# PIC16F1619 register map
File version: 1.0
Registers are 8-bit, read-write, reset 0x0 unless marked. A register's access mark holds for its fields unless they carry their own. Offsets are from the block's base; [hi:lo] are bit positions; {n}, {i} and the like mark numbered series.

## COMPARATORS
Base 0x00800111
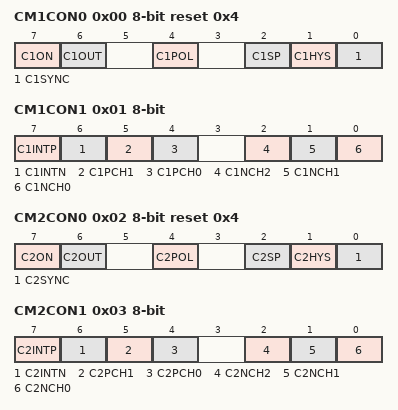
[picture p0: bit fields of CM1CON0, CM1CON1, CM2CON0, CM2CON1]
0x00 CM1CON0 reset 0x4 — CM1CON0, data address 0x111
  [7] C1ON, [6] C1OUT, [4] C1POL, [2] C1SP, [1] C1HYS, [0] C1SYNC
0x01 CM1CON1 — CM1CON1, data address 0x112
  [7] C1INTP, [6] C1INTN, [5] C1PCH1, [4] C1PCH0, [2] C1NCH2, [1] C1NCH1, [0] C1NCH0
0x02 CM2CON0 reset 0x4 — CM2CON0, data address 0x113
  [7] C2ON, [6] C2OUT, [4] C2POL, [2] C2SP, [1] C2HYS, [0] C2SYNC
0x03 CM2CON1 — CM2CON1, data address 0x114
  [7] C2INTP, [6] C2INTN, [5] C2PCH1, [4] C2PCH0, [2] C2NCH2, [1] C2NCH1, [0] C2NCH0
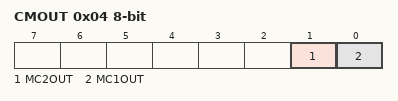
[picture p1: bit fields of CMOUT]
0x04 CMOUT — CMOUT, data address 0x115
  [1] MC2OUT, [0] MC1OUT

## EUSART
Base 0x00800199
0x00 RC1REG — RC1REG, data address 0x199
0x01 TX1REG — TX1REG, data address 0x19a
0x02 SP1BRGL — SP1BRGL, data address 0x19b
0x03 SP1BRGH — SP1BRGH, data address 0x19c
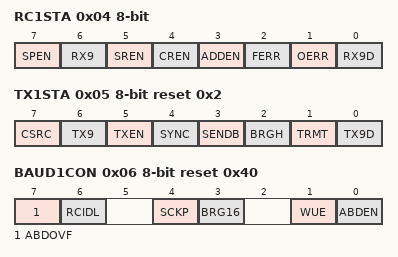
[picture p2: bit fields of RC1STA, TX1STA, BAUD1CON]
0x04 RC1STA — RC1STA, data address 0x19d
  [7] SPEN, [6] RX9, [5] SREN, [4] CREN, [3] ADDEN, [2] FERR, [1] OERR, [0] RX9D
0x05 TX1STA reset 0x2 — TX1STA, data address 0x19e
  [7] CSRC, [6] TX9, [5] TXEN, [4] SYNC, [3] SENDB, [2] BRGH, [1] TRMT, [0] TX9D
0x06 BAUD1CON reset 0x40 — BAUD1CON, data address 0x19f
  [7] ABDOVF, [6] RCIDL, [4] SCKP, [3] BRG16, [1] WUE, [0] ABDEN

## INTERRUPTS — Interrupt flags and enables
Base 0x00800010
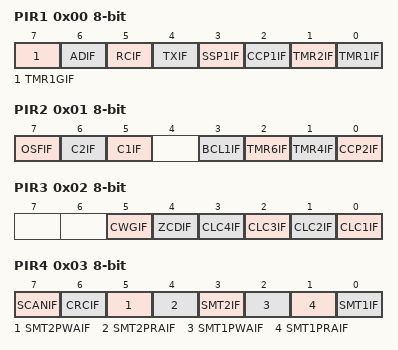
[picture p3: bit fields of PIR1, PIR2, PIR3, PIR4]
0x00 PIR1 — PIR1, data address 0x010
  [7] TMR1GIF, [6] ADIF, [5] RCIF, [4] TXIF, [3] SSP1IF, [2] CCP1IF, [1] TMR2IF, [0] TMR1IF
0x01 PIR2 — PIR2, data address 0x011
  [7] OSFIF, [6] C2IF, [5] C1IF, [3] BCL1IF, [2] TMR6IF, [1] TMR4IF, [0] CCP2IF
0x02 PIR3 — PIR3, data address 0x012
  [5] CWGIF, [4] ZCDIF, [n-1] CLC{n}IF (n=1..4)
0x03 PIR4 — PIR4, data address 0x013
  [7] SCANIF, [6] CRCIF, [5] SMT2PWAIF, [4] SMT2PRAIF, [3] SMT2IF, [2] SMT1PWAIF, [1] SMT1PRAIF, [0] SMT1IF
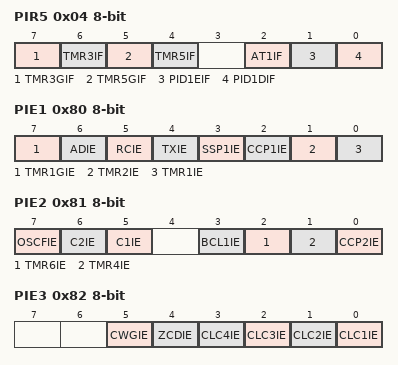
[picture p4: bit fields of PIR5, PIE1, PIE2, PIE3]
0x04 PIR5 — PIR5, data address 0x014
  [7] TMR3GIF, [6] TMR3IF, [5] TMR5GIF, [4] TMR5IF, [2] AT1IF, [1] PID1EIF, [0] PID1DIF
0x80 PIE1 — PIE1, data address 0x090
  [7] TMR1GIE, [6] ADIE, [5] RCIE, [4] TXIE, [3] SSP1IE, [2] CCP1IE, [1] TMR2IE, [0] TMR1IE
0x81 PIE2 — PIE2, data address 0x091
  [7] OSCFIE, [6] C2IE, [5] C1IE, [3] BCL1IE, [2] TMR6IE, [1] TMR4IE, [0] CCP2IE
0x82 PIE3 — PIE3, data address 0x092
  [5] CWGIE, [4] ZCDIE, [n-1] CLC{n}IE (n=1..4)
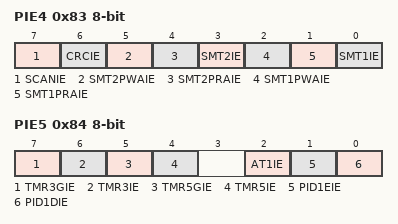
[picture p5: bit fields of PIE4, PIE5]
0x83 PIE4 — PIE4, data address 0x093
  [7] SCANIE, [6] CRCIE, [5] SMT2PWAIE, [4] SMT2PRAIE, [3] SMT2IE, [2] SMT1PWAIE, [1] SMT1PRAIE, [0] SMT1IE
0x84 PIE5 reset not defined — PIE5, data address 0x094
  [7] TMR3GIE, [6] TMR3IE, [5] TMR5GIE, [4] TMR5IE, [2] AT1IE, [1] PID1EIE, [0] PID1DIE

## MSSP — Synchronous serial port
Base 0x00800211
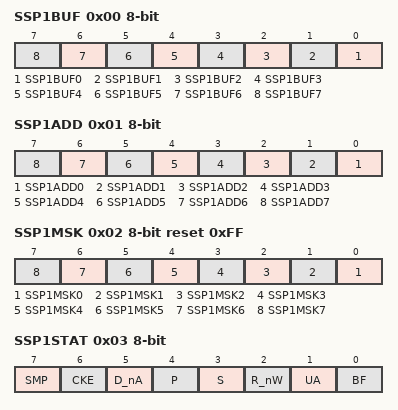
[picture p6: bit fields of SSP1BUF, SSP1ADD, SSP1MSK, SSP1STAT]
0x00 SSP1BUF reset not defined — SSP1BUF, data address 0x211
  [n] SSP1BUF{n} (n=0..7)
0x01 SSP1ADD — SSP1ADD, data address 0x212
  [n] SSP1ADD{n} (n=0..7)
0x02 SSP1MSK reset 0xFF — SSP1MSK, data address 0x213
  [n] SSP1MSK{n} (n=0..7)
0x03 SSP1STAT — SSP1STAT, data address 0x214
  [7] SMP, [6] CKE, [5] D_nA, [4] P, [3] S, [2] R_nW, [1] UA, [0] BF
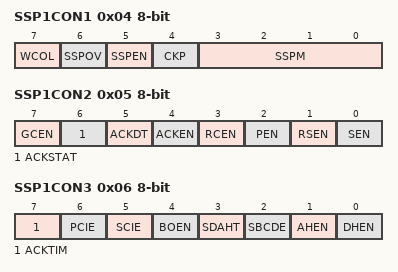
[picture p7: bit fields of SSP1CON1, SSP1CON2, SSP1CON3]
0x04 SSP1CON1 — SSP1CON1, data address 0x215
  [7] WCOL, [6] SSPOV, [5] SSPEN, [4] CKP, [3:0] SSPM
0x05 SSP1CON2 — SSP1CON2, data address 0x216
  [7] GCEN, [6] ACKSTAT, [5] ACKDT, [4] ACKEN, [3] RCEN, [2] PEN, [1] RSEN, [0] SEN
0x06 SSP1CON3 — SSP1CON3, data address 0x217
  [7] ACKTIM, [6] PCIE, [5] SCIE, [4] BOEN, [3] SDAHT, [2] SBCDE, [1] AHEN, [0] DHEN
0xC0F SSPCLKPPS reset 0xE — SSPCLKPPS, data address 0xe20
  [4:0] SSPCLKPPS
0xC10 SSPDATPPS reset 0xC — SSPDATPPS, data address 0xe21
  [4:0] SSPDATPPS
0xC11 SSPSSPPS reset 0x13 — SSPSSPPS, data address 0xe22
  [4:0] SSPSSPPS

## NVM — Flash and EEPROM access
Base 0x00800191
0x00 PMADRL — PMADRL, data address 0x191
0x01 PMADRH reset 0x80 — PMADRH, data address 0x192
  [6:0] PMADRH
0x02 PMDATL reset not defined — PMDATL, data address 0x193
0x03 PMDATH reset not defined — PMDATH, data address 0x194
  [5:0] PMDATH
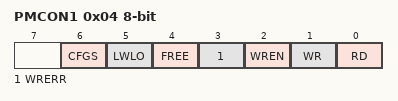
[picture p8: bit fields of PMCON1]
0x04 PMCON1 (reset mask 0x77) — PMCON1, data address 0x195
  [6] CFGS, [5] LWLO, [4] FREE, [3] WRERR, [2] WREN, [1] WR, [0] RD
0x05 PMCON2 — PMCON2, data address 0x196
